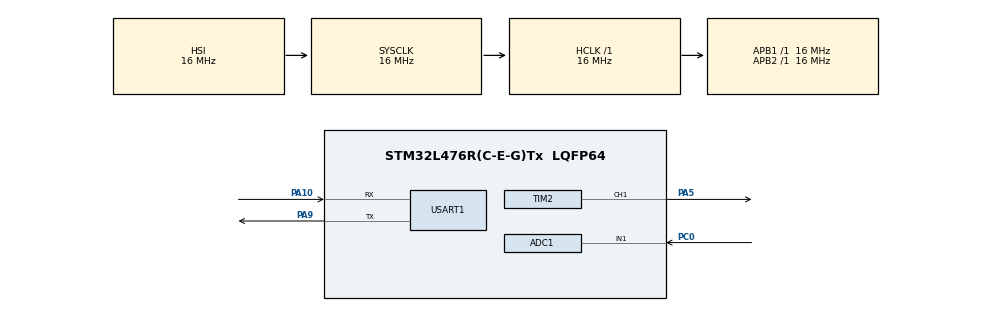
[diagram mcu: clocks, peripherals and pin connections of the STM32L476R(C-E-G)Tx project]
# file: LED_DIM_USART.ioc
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ADC1.Channel-0\#ChannelRegularConversion=ADC_CHANNEL_1
ADC1.ContinuousConvMode=DISABLE
ADC1.NbrOfConversionFlag=1
ADC1.OffsetNumber-0\#ChannelRegularConversion=ADC_OFFSET_NONE
ADC1.Rank-0\#ChannelRegularConversion=1
ADC1.SamplingTime-0\#ChannelRegularConversion=ADC_SAMPLETIME_2CYCLES_5
ADC1.master=1
Mcu.Family=STM32L4
Mcu.Name=STM32L476R(C-E-G)Tx
Mcu.Package=LQFP64
NVIC.PriorityGroup=NVIC_PRIORITYGROUP_4
PA10.Mode=Asynchronous
PA10.Signal=USART1_RX
PA13\ (JTMS-SWDIO).Mode=Serial_Wire
PA13\ (JTMS-SWDIO).Signal=SYS_JTMS-SWDIO
PA14\ (JTCK-SWCLK).Mode=Serial_Wire
PA14\ (JTCK-SWCLK).Signal=SYS_JTCK-SWCLK
PA5.Signal=S_TIM2_CH1
PA9.Mode=Asynchronous
PA9.Signal=USART1_TX
PC0.Signal=ADCx_IN1
ProjectManager.HeapSize=0x200
ProjectManager.StackSize=0x400
ProjectManager.TargetToolchain=STM32CubeIDE
RCC.ADCCLockSelection=RCC_ADCCLKSOURCE_SYSCLK
RCC.ADCFreq_Value=16000000
RCC.AHBFreq_Value=16000000
RCC.APB1Freq_Value=16000000
RCC.APB1TimFreq_Value=16000000
RCC.APB2Freq_Value=16000000
RCC.APB2TimFreq_Value=16000000
RCC.CortexFreq_Value=16000000
RCC.HCLKFreq_Value=16000000
RCC.HSE_VALUE=8000000
RCC.HSI_VALUE=16000000
RCC.MSI_VALUE=4000000
RCC.PLLN=10
RCC.PLLSourceVirtual=RCC_PLLSOURCE_HSI
RCC.PREFETCH_ENABLE=1
RCC.SYSCLKFreq_VALUE=16000000
RCC.SYSCLKSource=RCC_SYSCLKSOURCE_HSI
RCC.USBFreq_Value=64000000
RCC.VCOOutputFreq_Value=160000000
SH.ADCx_IN1.0=ADC1_IN1,IN1-Single-Ended
SH.S_TIM2_CH1.0=TIM2_CH1,PWM Generation1 CH1
TIM2.Channel-PWM\ Generation1\ CH1=TIM_CHANNEL_1
TIM2.Period=4096 - 1
TIM2.Prescaler=16 - 1
USART1.VirtualMode-Asynchronous=VM_ASYNC
VP_TIM2_VS_ClockSourceINT.Mode=Internal
board=NUCLEO-L476RG

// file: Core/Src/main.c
/* USER CODE BEGIN Header */
/**
  ******************************************************************************
  * @file           : main.c
  * @brief          : Main program body
  ******************************************************************************
  * @attention
  *
  * Copyright (c) 2024 STMicroelectronics.
  * All rights reserved.
  *
  * This software is licensed under terms that can be found in the LICENSE file
  * in the root directory of this software component.
  * If no LICENSE file comes with this software, it is provided AS-IS.
  *
  ******************************************************************************
  */
/* USER CODE END Header */
#include "main.h"
#include <string.h>
#include <stdio.h>
#include <stdlib.h>

ADC_HandleTypeDef hadc1;

TIM_HandleTypeDef htim2;

UART_HandleTypeDef huart1;

void SystemClock_Config(void);
static void MX_GPIO_Init(void);
static void MX_ADC1_Init(void);
static void MX_TIM2_Init(void);
static void MX_USART1_UART_Init(void);
/* USER CODE BEGIN PFP */
uint32_t ADCValue;
const float REF_VOLTAGE = 3.3; // Reference voltage in volts
const uint32_t ADC_RESOLUTION = 4096; // 12-bit resolution
float voltage;
char str[20];
/* USER CODE END PFP */

int main(void)
{

  /* MCU Configuration--------------------------------------------------------*/

  /* Reset of all peripherals, Initializes the Flash interface and the Systick. */
  HAL_Init();

  /* Configure the system clock */
  SystemClock_Config();

  /* Initialize all configured peripherals */
  MX_GPIO_Init();
  MX_ADC1_Init();
  MX_TIM2_Init();
  MX_USART1_UART_Init();
  /* USER CODE BEGIN 2 */
  HAL_ADCEx_Calibration_Start(&hadc1, ADC_SINGLE_ENDED);
  /* USER CODE END 2 */

  /* Infinite loop */
  while (1)
  {
	  HAL_ADC_Start(&hadc1);
	  HAL_ADC_PollForConversion(&hadc1, 1000000);
	  ADCValue = HAL_ADC_GetValue(&hadc1);
	  voltage = (ADCValue / (float)ADC_RESOLUTION) * REF_VOLTAGE;
	  sprintf(str, "Voltage is %.2f V\n", voltage); // %.2f for 2 decimal places
	  HAL_UART_Transmit(&huart1, (uint8_t*)str, strlen(str), 100);
  }
}

void SystemClock_Config(void)
{
  RCC_OscInitTypeDef RCC_OscInitStruct = {0};
  RCC_ClkInitTypeDef RCC_ClkInitStruct = {0};

  /** Configure the main internal regulator output voltage
  */
  if (HAL_PWREx_ControlVoltageScaling(PWR_REGULATOR_VOLTAGE_SCALE1) != HAL_OK)
  {
    Error_Handler();
  }

  /** Initializes the RCC Oscillators according to the specified parameters
  * in the RCC_OscInitTypeDef structure.
  */
  RCC_OscInitStruct.OscillatorType = RCC_OSCILLATORTYPE_HSI;
  RCC_OscInitStruct.HSIState = RCC_HSI_ON;
  RCC_OscInitStruct.HSICalibrationValue = RCC_HSICALIBRATION_DEFAULT;
  RCC_OscInitStruct.PLL.PLLState = RCC_PLL_NONE;
  if (HAL_RCC_OscConfig(&RCC_OscInitStruct) != HAL_OK)
  {
    Error_Handler();
  }

  /** Initializes the CPU, AHB and APB buses clocks
  */
  RCC_ClkInitStruct.ClockType = RCC_CLOCKTYPE_HCLK|RCC_CLOCKTYPE_SYSCLK
                              |RCC_CLOCKTYPE_PCLK1|RCC_CLOCKTYPE_PCLK2;
  RCC_ClkInitStruct.SYSCLKSource = RCC_SYSCLKSOURCE_HSI;
  RCC_ClkInitStruct.AHBCLKDivider = RCC_SYSCLK_DIV1;
  RCC_ClkInitStruct.APB1CLKDivider = RCC_HCLK_DIV1;
  RCC_ClkInitStruct.APB2CLKDivider = RCC_HCLK_DIV1;

  if (HAL_RCC_ClockConfig(&RCC_ClkInitStruct, FLASH_LATENCY_0) != HAL_OK)
  {
    Error_Handler();
  }
}

static void MX_ADC1_Init(void)
{

  ADC_MultiModeTypeDef multimode = {0};
  ADC_ChannelConfTypeDef sConfig = {0};

  /** Common config
  */
  hadc1.Instance = ADC1;
  hadc1.Init.ClockPrescaler = ADC_CLOCK_ASYNC_DIV1;
  hadc1.Init.Resolution = ADC_RESOLUTION_12B;
  hadc1.Init.DataAlign = ADC_DATAALIGN_RIGHT;
  hadc1.Init.ScanConvMode = ADC_SCAN_DISABLE;
  hadc1.Init.EOCSelection = ADC_EOC_SINGLE_CONV;
  hadc1.Init.LowPowerAutoWait = DISABLE;
  hadc1.Init.ContinuousConvMode = DISABLE;
  hadc1.Init.NbrOfConversion = 1;
  hadc1.Init.DiscontinuousConvMode = DISABLE;
  hadc1.Init.ExternalTrigConv = ADC_SOFTWARE_START;
  hadc1.Init.ExternalTrigConvEdge = ADC_EXTERNALTRIGCONVEDGE_NONE;
  hadc1.Init.DMAContinuousRequests = DISABLE;
  hadc1.Init.Overrun = ADC_OVR_DATA_PRESERVED;
  hadc1.Init.OversamplingMode = DISABLE;
  if (HAL_ADC_Init(&hadc1) != HAL_OK)
  {
    Error_Handler();
  }

  /** Configure the ADC multi-mode
  */
  multimode.Mode = ADC_MODE_INDEPENDENT;
  if (HAL_ADCEx_MultiModeConfigChannel(&hadc1, &multimode) != HAL_OK)
  {
    Error_Handler();
  }

  /** Configure Regular Channel
  */
  sConfig.Channel = ADC_CHANNEL_1;
  sConfig.Rank = ADC_REGULAR_RANK_1;
  sConfig.SamplingTime = ADC_SAMPLETIME_2CYCLES_5;
  sConfig.SingleDiff = ADC_SINGLE_ENDED;
  sConfig.OffsetNumber = ADC_OFFSET_NONE;
  sConfig.Offset = 0;
  if (HAL_ADC_ConfigChannel(&hadc1, &sConfig) != HAL_OK)
  {
    Error_Handler();
  }

}

static void MX_TIM2_Init(void)
{

  TIM_ClockConfigTypeDef sClockSourceConfig = {0};
  TIM_MasterConfigTypeDef sMasterConfig = {0};
  TIM_OC_InitTypeDef sConfigOC = {0};

  htim2.Instance = TIM2;
  htim2.Init.Prescaler = 16 - 1;
  htim2.Init.CounterMode = TIM_COUNTERMODE_UP;
  htim2.Init.Period = 4096 - 1;
  htim2.Init.ClockDivision = TIM_CLOCKDIVISION_DIV1;
  htim2.Init.AutoReloadPreload = TIM_AUTORELOAD_PRELOAD_DISABLE;
  if (HAL_TIM_Base_Init(&htim2) != HAL_OK)
  {
    Error_Handler();
  }
  sClockSourceConfig.ClockSource = TIM_CLOCKSOURCE_INTERNAL;
  if (HAL_TIM_ConfigClockSource(&htim2, &sClockSourceConfig) != HAL_OK)
  {
    Error_Handler();
  }
  if (HAL_TIM_PWM_Init(&htim2) != HAL_OK)
  {
    Error_Handler();
  }
  sMasterConfig.MasterOutputTrigger = TIM_TRGO_RESET;
  sMasterConfig.MasterSlaveMode = TIM_MASTERSLAVEMODE_DISABLE;
  if (HAL_TIMEx_MasterConfigSynchronization(&htim2, &sMasterConfig) != HAL_OK)
  {
    Error_Handler();
  }
  sConfigOC.OCMode = TIM_OCMODE_PWM1;
  sConfigOC.Pulse = 0;
  sConfigOC.OCPolarity = TIM_OCPOLARITY_HIGH;
  sConfigOC.OCFastMode = TIM_OCFAST_DISABLE;
  if (HAL_TIM_PWM_ConfigChannel(&htim2, &sConfigOC, TIM_CHANNEL_1) != HAL_OK)
  {
    Error_Handler();
  }
  HAL_TIM_MspPostInit(&htim2);

}

static void MX_USART1_UART_Init(void)
{

  huart1.Instance = USART1;
  huart1.Init.BaudRate = 115200;
  huart1.Init.WordLength = UART_WORDLENGTH_8B;
  huart1.Init.StopBits = UART_STOPBITS_1;
  huart1.Init.Parity = UART_PARITY_NONE;
  huart1.Init.Mode = UART_MODE_TX_RX;
  huart1.Init.HwFlowCtl = UART_HWCONTROL_NONE;
  huart1.Init.OverSampling = UART_OVERSAMPLING_16;
  huart1.Init.OneBitSampling = UART_ONE_BIT_SAMPLE_DISABLE;
  huart1.AdvancedInit.AdvFeatureInit = UART_ADVFEATURE_NO_INIT;
  if (HAL_UART_Init(&huart1) != HAL_OK)
  {
    Error_Handler();
  }

}

static void MX_GPIO_Init(void)
{

  /* GPIO Ports Clock Enable */
  __HAL_RCC_GPIOC_CLK_ENABLE();
  __HAL_RCC_GPIOA_CLK_ENABLE();

}

void Error_Handler(void)
{
  __disable_irq();
  while (1)
  {
  }
}
